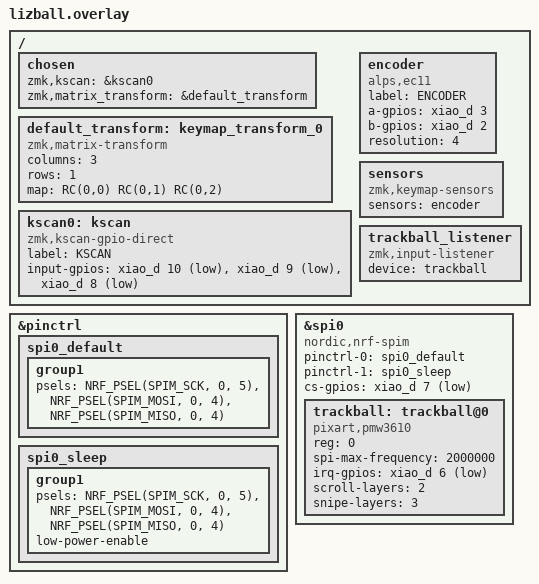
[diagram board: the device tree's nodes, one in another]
#include <dt-bindings/zmk/matrix_transform.h>

/ {
    chosen {
        zmk,kscan = &kscan0;
        zmk,matrix_transform = &default_transform;
    };

    default_transform: keymap_transform_0 {
        compatible = "zmk,matrix-transform";
        columns = <3>;
        rows = <1>;
        map = <
            RC(0,0) RC(0,1) RC(0,2)
        >;
    };

    kscan0: kscan {
        compatible = "zmk,kscan-gpio-direct";
        label = "KSCAN";

        input-gpios =
            <&xiao_d 10 (GPIO_PULL_UP | GPIO_ACTIVE_LOW)>,  // Switch 1 (left)
            <&xiao_d 9  (GPIO_PULL_UP | GPIO_ACTIVE_LOW)>,  // Switch 2 (center)
            <&xiao_d 8  (GPIO_PULL_UP | GPIO_ACTIVE_LOW)>;  // Switch 3 (right)
    };

    encoder: encoder {
        compatible = "alps,ec11";
        label = "ENCODER";
        a-gpios = <&xiao_d 3 (GPIO_ACTIVE_HIGH | GPIO_PULL_UP)>;  // P0.29 (A3/D3)
        b-gpios = <&xiao_d 2 (GPIO_ACTIVE_HIGH | GPIO_PULL_UP)>;  // P0.28 (A2/D2) 
        resolution = <4>;
    };

    sensors {
        compatible = "zmk,keymap-sensors";
        sensors = <&encoder>;
    };

    trackball_listener {
        compatible = "zmk,input-listener";
        device = <&trackball>;
    };
};

&pinctrl {
    spi0_default: spi0_default {
        group1 {
            psels = <NRF_PSEL(SPIM_SCK, 0, 5)>,  // P0.05 (D5/SCL)
                   <NRF_PSEL(SPIM_MOSI, 0, 4)>,  // P0.04 (D4/SDA)
                   <NRF_PSEL(SPIM_MISO, 0, 4)>;  // Same pin - SDIO bidirectional
        };
    };

    spi0_sleep: spi0_sleep {
        group1 {
            psels = <NRF_PSEL(SPIM_SCK, 0, 5)>,
                   <NRF_PSEL(SPIM_MOSI, 0, 4)>,
                   <NRF_PSEL(SPIM_MISO, 0, 4)>;
            low-power-enable;
        };
    };
};

&spi0 {
    status = "okay";
    compatible = "nordic,nrf-spim";
    pinctrl-0 = <&spi0_default>;
    pinctrl-1 = <&spi0_sleep>;
    pinctrl-names = "default", "sleep";
    cs-gpios = <&xiao_d 7 GPIO_ACTIVE_LOW>;  // P1.12 (D7/RX)
    
    trackball: trackball@0 {
        status = "okay";
        compatible = "pixart,pmw3610";
        reg = <0>;
        spi-max-frequency = <2000000>;
        irq-gpios = <&xiao_d 6 (GPIO_ACTIVE_LOW | GPIO_PULL_UP)>;  // P1.11 (D6/TX)
        
        scroll-layers = <2>;    // Layer 2 for scrolling
        snipe-layers = <3>;     // Layer 3 for precision movement
    };
};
